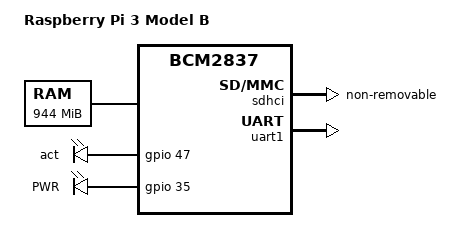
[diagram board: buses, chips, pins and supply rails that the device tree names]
/dts-v1/;
#include "bcm2837.dtsi"
#include "bcm2835-rpi.dtsi"
#include "bcm283x-rpi-smsc9514.dtsi"

/ {
	compatible = "raspberrypi,3-model-b", "brcm,bcm2837";
	model = "Raspberry Pi 3 Model B";

	memory {
		reg = <0 0x3b000000>;
	};

	leds {
		act {
			gpios = <&gpio 47 0>;
		};

		pwr {
			label = "PWR";
			gpios = <&gpio 35 0>;
			default-state = "keep";
			linux,default-trigger = "default-on";
		};
	};
};

&gpio {
	pinctrl-0 = <&gpioout &alt0>;
	alt3: alt3 {
		brcm,pins = <34 35 36 37 38 39>;
		brcm,function = <BCM2835_FSEL_ALT3>;
		brcm,pull = <0 2 2 2 2 2>;
	};
};

&sdhci {
	status = "okay";
	non-removable;
	pinctrl-names = "default";
	pinctrl-0 = <&alt3>;
};

&uart1 {
	status = "okay";
};
